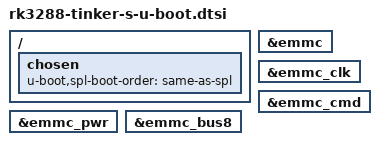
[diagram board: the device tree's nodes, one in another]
// SPDX-License-Identifier: GPL-2.0+
/*
 * Copyright (C) 2019 Amarula Solutions SRO
 */

#include "rk3288-u-boot.dtsi"
#include "rk3288-tinker-u-boot.dtsi"

/ {
	chosen {
		u-boot,spl-boot-order = \
			"same-as-spl", &sdmmc, &emmc;
	};
};

&emmc {
	u-boot,dm-spl;
};

&emmc_clk {
	u-boot,dm-spl;
};

&emmc_cmd {
	u-boot,dm-spl;
};

&emmc_pwr {
	u-boot,dm-spl;
};

&emmc_bus8 {
	u-boot,dm-spl;
};
